# PIC32CZ1038CA70144 register map
Vendor: Microchip Technology; Series: PIC32CZCA70; File version: 0
CPU: CM7 r1p1, little endian, MPU, FPU, double-precision FPU, I-cache, D-cache, ITCM, DTCM, 3 interrupt priority bits, 74 interrupts
Registers are 32-bit, read-write, reset 0x0 unless marked. A register's access mark holds for its fields unless they carry their own. Offsets are from the block's base; [hi:lo] are bit positions; lines under a group give offsets from that group; {n}, {i} and the like mark numbered series; 'fields as' and 'values as' point back to an identical list.

## GMAC — Gigabit Ethernet MAC
Base 0x40050000
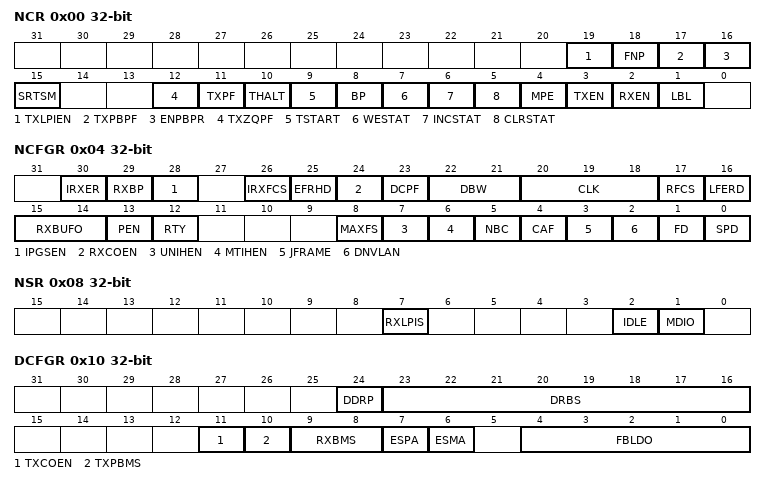
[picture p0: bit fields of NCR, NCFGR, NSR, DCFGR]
0x00 NCR — Network Control Register
  [19] TXLPIEN — Enable LPI Transmission
  [18] FNP — Flush Next Packet
  [17] TXPBPF — Transmit PFC Priority-based Pause Frame
  [16] ENPBPR — Enable PFC Priority-based Pause Reception
  [15] SRTSM — Store Receive Time Stamp to Memory
  [12] TXZQPF — Transmit Zero Quantum Pause Frame
  [11] TXPF — Transmit Pause Frame
  [10] THALT — Transmit Halt
  [9] TSTART — Start Transmission
  [8] BP — Back pressure
  [7] WESTAT — Write Enable for Statistics Registers
  [6] INCSTAT — Increment Statistics Registers
  [5] CLRSTAT — Clear Statistics Registers
  [4] MPE — Management Port Enable
  [3] TXEN — Transmit Enable
  [2] RXEN — Receive Enable
  [1] LBL — Loop Back Local
0x04 NCFGR — Network Configuration Register
  [30] IRXER — Ignore IPG GRXER
  [29] RXBP — Receive Bad Preamble
  [28] IPGSEN — IP Stretch Enable
  [26] IRXFCS — Ignore RX FCS
  [25] EFRHD — Enable Frames Received in Half Duplex
  [24] RXCOEN — Receive Checksum Offload Enable
  [23] DCPF — Disable Copy of Pause Frames
  [22:21] DBW — Data Bus Width
  [20:18] CLK — MDC CLock Division
    0=MCK_8 (MCK divided by 8 (MCK up to 20 MHz)); 1=MCK_16 (MCK divided by 16 (MCK up to 40 MHz)); 2=MCK_32 (MCK divided by 32 (MCK up to 80 MHz)); 3=MCK_48 (MCK divided by 48 (MCK up to 120 MHz)); 4=MCK_64 (MCK divided by 64 (MCK up to 160 MHz)); 5=MCK_96 (MCK divided by 96 (MCK up to 240 MHz))
  [17] RFCS — Remove FCS
  [16] LFERD — Length Field Error Frame Discard
  [15:14] RXBUFO — Receive Buffer Offset
  [13] PEN — Pause Enable
  [12] RTY — Retry Test
  [8] MAXFS — 1536 Maximum Frame Size
  [7] UNIHEN — Unicast Hash Enable
  [6] MTIHEN — Multicast Hash Enable
  [5] NBC — No Broadcast
  [4] CAF — Copy All Frames
  [3] JFRAME — Jumbo Frame Size
  [2] DNVLAN — Discard Non-VLAN FRAMES
  [1] FD — Full Duplex
  [0] SPD — Speed
0x08 NSR ro — Network Status Register
  [7] RXLPIS — LPI Indication
  [2] IDLE — PHY Management Logic Idle
  [1] MDIO — MDIO Input Status
0x0C UR — User Register
  [0] RMII — Reduced MII Mode
0x10 DCFGR — DMA Configuration Register
  [24] DDRP — DMA Discard Receive Packets
  [23:16] DRBS — DMA Receive Buffer Size
  [11] TXCOEN — Transmitter Checksum Generation Offload Enable
  [10] TXPBMS — Transmitter Packet Buffer Memory Size Select
  [9:8] RXBMS — Receiver Packet Buffer Memory Size Select
    0=EIGHTH (4/8 Kbyte Memory Size); 1=QUARTER (4/4 Kbytes Memory Size); 2=HALF (4/2 Kbytes Memory Size); 3=FULL (4 Kbytes Memory Size)
  [7] ESPA — Endian Swap Mode Enable for Packet Data Accesses
  [6] ESMA — Endian Swap Mode Enable for Management Descriptor Accesses
  [4:0] FBLDO — Fixed Burst Length for DMA Data Operations:
    1=SINGLE (00001: Always use SINGLE AHB bursts); 4=INCR4 (001xx: Attempt to use INCR4 AHB bursts (Default)); 8=INCR8 (01xxx: Attempt to use INCR8 AHB bursts); 16=INCR16 (1xxxx: Attempt to use INCR16 AHB bursts)
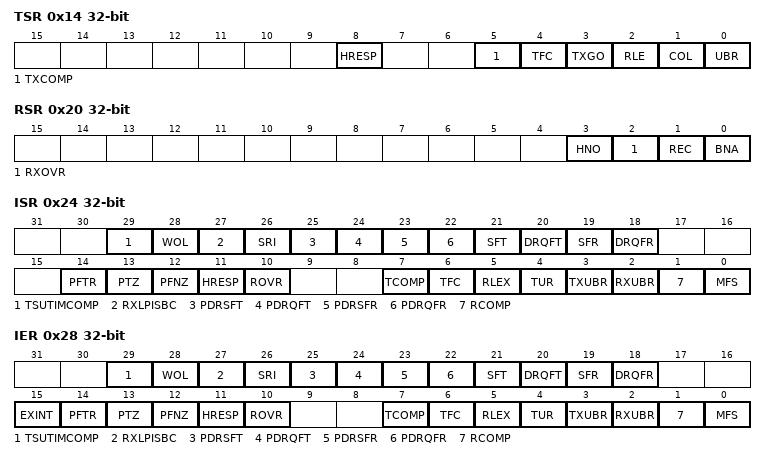
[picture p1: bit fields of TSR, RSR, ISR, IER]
0x14 TSR — Transmit Status Register
  [8] HRESP — HRESP Not OK
  [5] TXCOMP — Transmit Complete
  [4] TFC — Transmit Frame Corruption Due to AHB Error
  [3] TXGO — Transmit Go
  [2] RLE — Retry Limit Exceeded
  [1] COL — Collision Occurred
  [0] UBR — Used Bit Read
0x18 RBQB — Receive Buffer Queue Base Address Register
  [31:2] ADDR — Receive Buffer Queue Base Address
0x1C TBQB — Transmit Buffer Queue Base Address Register
  [31:2] ADDR — Transmit Buffer Queue Base Address
0x20 RSR — Receive Status Register
  [3] HNO — HRESP Not OK
  [2] RXOVR — Receive Overrun
  [1] REC — Frame Received
  [0] BNA — Buffer Not Available
0x24 ISR ro — Interrupt Status Register
  [29] TSUTIMCOMP — TSU Timer Comparison
  [28] WOL — Wake On LAN
  [27] RXLPISBC — Receive LPI indication Status Bit Change
  [26] SRI — TSU Seconds Register Increment
  [25] PDRSFT — PDelay Response Frame Transmitted
  [24] PDRQFT — PDelay Request Frame Transmitted
  [23] PDRSFR — PDelay Response Frame Received
  [22] PDRQFR — PDelay Request Frame Received
  [21] SFT — PTP Sync Frame Transmitted
  [20] DRQFT — PTP Delay Request Frame Transmitted
  [19] SFR — PTP Sync Frame Received
  [18] DRQFR — PTP Delay Request Frame Received
  [14] PFTR — Pause Frame Transmitted
  [13] PTZ — Pause Time Zero
  [12] PFNZ — Pause Frame with Non-zero Pause Quantum Received
  [11] HRESP — HRESP Not OK
  [10] ROVR — Receive Overrun
  [7] TCOMP — Transmit Complete
  [6] TFC — Transmit Frame Corruption Due to AHB Error
  [5] RLEX — Retry Limit Exceeded
  [4] TUR — Transmit Underrun
  [3] TXUBR — TX Used Bit Read
  [2] RXUBR — RX Used Bit Read
  [1] RCOMP — Receive Complete
  [0] MFS — Management Frame Sent
0x28 IER wo — Interrupt Enable Register
  [29] TSUTIMCOMP — TSU Timer Comparison
  [28] WOL — Wake On LAN
  [27] RXLPISBC — Enable RX LPI Indication
  [26] SRI — TSU Seconds Register Increment
  [25] PDRSFT — PDelay Response Frame Transmitted
  [24] PDRQFT — PDelay Request Frame Transmitted
  [23] PDRSFR — PDelay Response Frame Received
  [22] PDRQFR — PDelay Request Frame Received
  [21] SFT — PTP Sync Frame Transmitted
  [20] DRQFT — PTP Delay Request Frame Transmitted
  [19] SFR — PTP Sync Frame Received
  [18] DRQFR — PTP Delay Request Frame Received
  [15] EXINT — External Interrupt
  [14] PFTR — Pause Frame Transmitted
  [13] PTZ — Pause Time Zero
  [12] PFNZ — Pause Frame with Non-zero Pause Quantum Received
  [11] HRESP — HRESP Not OK
  [10] ROVR — Receive Overrun
  [7] TCOMP — Transmit Complete
  [6] TFC — Transmit Frame Corruption Due to AHB Error
  [5] RLEX — Retry Limit Exceeded or Late Collision
  [4] TUR — Transmit Underrun
  [3] TXUBR — TX Used Bit Read
  [2] RXUBR — RX Used Bit Read
  [1] RCOMP — Receive Complete
  [0] MFS — Management Frame Sent
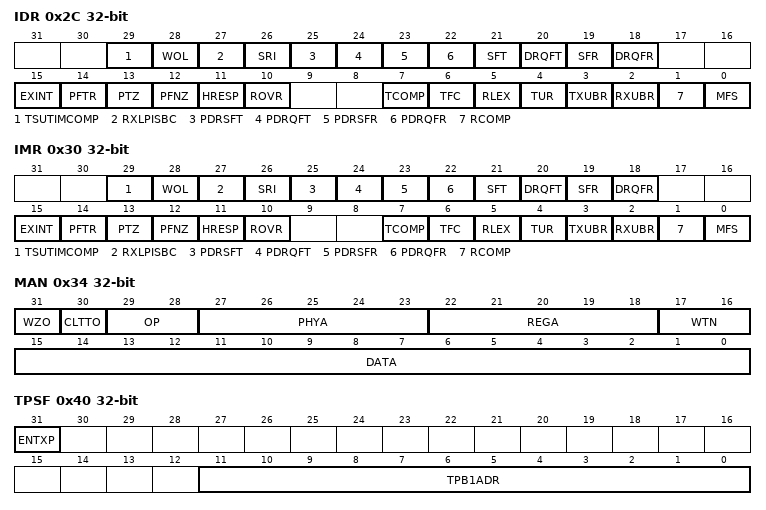
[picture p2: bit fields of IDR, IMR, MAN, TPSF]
0x2C IDR wo — Interrupt Disable Register
  fields as IER
0x30 IMR — Interrupt Mask Register
  [29] TSUTIMCOMP — TSU Timer Comparison
  [28] WOL — Wake On LAN
  [27] RXLPISBC — Enable RX LPI Indication
  [26] SRI — TSU Seconds Register Increment
  [25] PDRSFT — PDelay Response Frame Transmitted
  [24] PDRQFT — PDelay Request Frame Transmitted
  [23] PDRSFR — PDelay Response Frame Received
  [22] PDRQFR — PDelay Request Frame Received
  [21] SFT — PTP Sync Frame Transmitted
  [20] DRQFT — PTP Delay Request Frame Transmitted
  [19] SFR — PTP Sync Frame Received
  [18] DRQFR — PTP Delay Request Frame Received
  [15] EXINT — External Interrupt
  [14] PFTR — Pause Frame Transmitted
  [13] PTZ — Pause Time Zero
  [12] PFNZ — Pause Frame with Non-zero Pause Quantum Received
  [11] HRESP — HRESP Not OK
  [10] ROVR — Receive Overrun
  [7] TCOMP — Transmit Complete
  [6] TFC — Transmit Frame Corruption Due to AHB Error
  [5] RLEX — Retry Limit Exceeded
  [4] TUR — Transmit Underrun
  [3] TXUBR — TX Used Bit Read
  [2] RXUBR — RX Used Bit Read
  [1] RCOMP — Receive Complete
  [0] MFS — Management Frame Sent
0x34 MAN — PHY Maintenance Register
  [31] WZO — Write ZERO
  [30] CLTTO — Clause 22 Operation
  [29:28] OP — Operation
  [27:23] PHYA — PHY Address
  [22:18] REGA — Register Address
  [17:16] WTN — Write Ten
  [15:0] DATA — PHY Data
0x38 RPQ ro — Received Pause Quantum Register
  [15:0] RPQ — Received Pause Quantum
0x3C TPQ — Transmit Pause Quantum Register
  [15:0] TPQ — Transmit Pause Quantum
0x40 TPSF — TX Partial Store and Forward Register
  [31] ENTXP — Enable TX Partial Store and Forward Operation
  [11:0] TPB1ADR — Transmit Partial Store and Forward Address
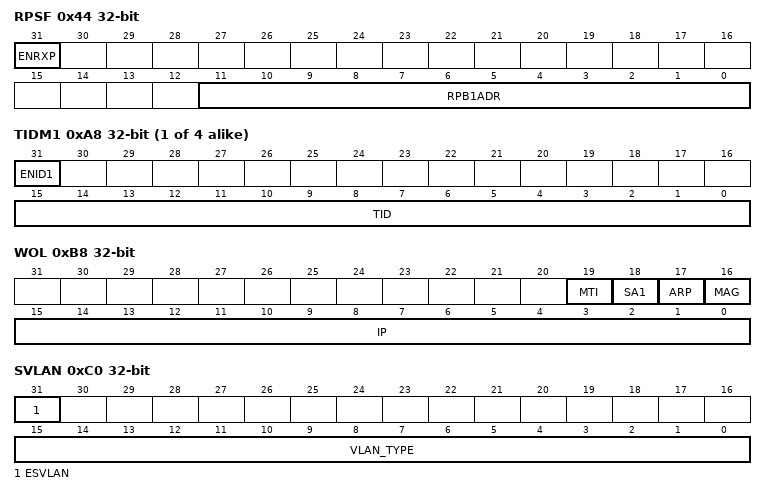
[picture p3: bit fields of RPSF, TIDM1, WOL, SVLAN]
0x44 RPSF — RX Partial Store and Forward Register
  [31] ENRXP — Enable RX Partial Store and Forward Operation
  [11:0] RPB1ADR — Receive Partial Store and Forward Address
0x48 RJFML — RX Jumbo Frame Max Length Register
  [13:0] FML — Frame Max Length
0x80 HRB — Hash Register Bottom
  [31:0] ADDR — Hash Address
0x84 HRT — Hash Register Top
  [31:0] ADDR — Hash Address
{0x80+8i} GMAC_SA{i} (i=1..4) group — Specific Address 1 Bottom Register
  0x00 SAB — Specific Address 1 Bottom Register
    [31:0] ADDR — Specific Address 1
  0x04 SAT — Specific Address 1 Top Register
    [15:0] ADDR — Specific Address 1
{0xA4+4i} TIDM{i} (i=1..4) — Type ID Match {i} Register
  [31] ENID{i} — Enable Copying of TID Matched Frames
  [15:0] TID — Type ID Match {i}
0xB8 WOL — Wake on LAN Register
  [19] MTI — Multicast Hash Event Enable
  [18] SA1 — Specific Address Register 1 Event Enable
  [17] ARP — ARP Request IP Address
  [16] MAG — Magic Packet Event Enable
  [15:0] IP — ARP Request IP Address
0xBC IPGS — IPG Stretch Register
  [15:0] FL — Frame Length
0xC0 SVLAN — Stacked VLAN Register
  [31] ESVLAN — Enable Stacked VLAN Processing Mode
  [15:0] VLAN_TYPE — User Defined VLAN_TYPE Field
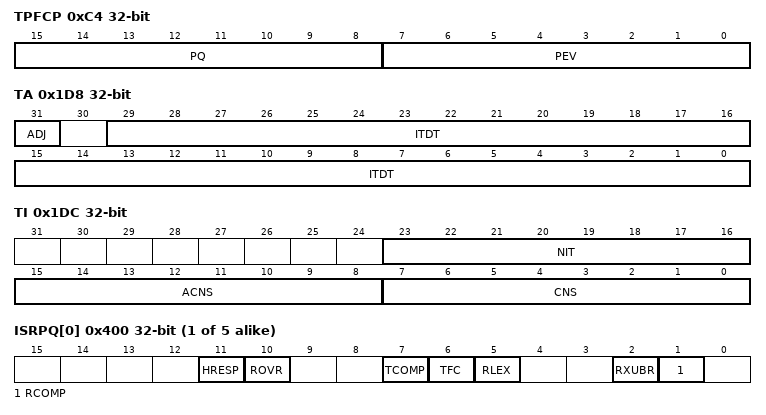
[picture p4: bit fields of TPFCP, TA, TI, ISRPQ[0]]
0xC4 TPFCP — Transmit PFC Pause Register
  [15:8] PQ — Pause Quantum
  [7:0] PEV — Priority Enable Vector
0xC8 SAMB1 — Specific Address 1 Mask Bottom Register
  [31:0] ADDR — Specific Address 1 Mask
0xCC SAMT1 — Specific Address 1 Mask Top Register
  [15:0] ADDR — Specific Address 1 Mask
0xDC NSC — 1588 Timer Nanosecond Comparison Register
  [21:0] NANOSEC — 1588 Timer Nanosecond Comparison Value
0xE0 SCL — 1588 Timer Second Comparison Low Register
  [31:0] SEC — 1588 Timer Second Comparison Value
0xE4 SCH — 1588 Timer Second Comparison High Register
  [15:0] SEC — 1588 Timer Second Comparison Value
0xE8 EFTSH ro — PTP Event Frame Transmitted Seconds High Register
  [15:0] RUD — Register Update
0xEC EFRSH ro — PTP Event Frame Received Seconds High Register
  [15:0] RUD — Register Update
0xF0 PEFTSH ro — PTP Peer Event Frame Transmitted Seconds High Register
  [15:0] RUD — Register Update
0xF4 PEFRSH ro — PTP Peer Event Frame Received Seconds High Register
  [15:0] RUD — Register Update
0x100 OTLO ro — Octets Transmitted Low Register
  [31:0] TXO — Transmitted Octets
0x104 OTHI ro — Octets Transmitted High Register
  [15:0] TXO — Transmitted Octets
0x108 FT ro — Frames Transmitted Register
  [31:0] FTX — Frames Transmitted without Error
0x10C BCFT ro — Broadcast Frames Transmitted Register
  [31:0] BFTX — Broadcast Frames Transmitted without Error
0x110 MFT ro — Multicast Frames Transmitted Register
  [31:0] MFTX — Multicast Frames Transmitted without Error
0x114 PFT ro — Pause Frames Transmitted Register
  [15:0] PFTX
0x118 BFT64 ro — 64 Byte Frames Transmitted Register
  [31:0] NFTX — 64 Byte Frames Transmitted without Error
0x11C TBFT127 ro — 65 to 127 Byte Frames Transmitted Register
  [31:0] NFTX — 65 to 127 Byte Frames Transmitted without Error
0x120 TBFT255 ro — 128 to 255 Byte Frames Transmitted Register
  [31:0] NFTX — 128 to 255 Byte Frames Transmitted without Error
0x124 TBFT511 ro — 256 to 511 Byte Frames Transmitted Register
  [31:0] NFTX — 256 to 511 Byte Frames Transmitted without Error
0x128 TBFT1023 ro — 512 to 1023 Byte Frames Transmitted Register
  [31:0] NFTX — 512 to 1023 Byte Frames Transmitted without Error
0x12C TBFT1518 ro — 1024 to 1518 Byte Frames Transmitted Register
  [31:0] NFTX — 1024 to 1518 Byte Frames Transmitted without Error
0x130 GTBFT1518 ro — Greater Than 1518 Byte Frames Transmitted Register
  [31:0] NFTX — Greater than 1518 Byte Frames Transmitted without Error
0x134 TUR ro — Transmit Underruns Register
  [9:0] TXUNR — Transmit Underruns
0x138 SCF ro — Single Collision Frames Register
  [17:0] SCOL — Single Collision
0x13C MCF ro — Multiple Collision Frames Register
  [17:0] MCOL — Multiple Collision
0x140 EC ro — Excessive Collisions Register
  [9:0] XCOL — Excessive Collisions
0x144 LC ro — Late Collisions Register
  [9:0] LCOL — Late Collisions
0x148 DTF ro — Deferred Transmission Frames Register
  [17:0] DEFT — Deferred Transmission
0x14C CSE ro — Carrier Sense Errors Register
  [9:0] CSR — Carrier Sense Error
0x150 ORLO ro — Octets Received Low Received Register
  [31:0] RXO — Received Octets
0x154 ORHI ro — Octets Received High Received Register
  [15:0] RXO — Received Octets
0x158 FR ro — Frames Received Register
  [31:0] FRX — Frames Received without Error
0x15C BCFR ro — Broadcast Frames Received Register
  [31:0] BFRX — Broadcast Frames Received without Error
0x160 MFR ro — Multicast Frames Received Register
  [31:0] MFRX — Multicast Frames Received without Error
0x164 PFR ro — Pause Frames Received Register
  [15:0] PFRX
0x168 BFR64 ro — 64 Byte Frames Received Register
  [31:0] NFRX — 64 Byte Frames Received without Error
0x16C TBFR127 ro — 65 to 127 Byte Frames Received Register
  [31:0] NFRX — 65 to 127 Byte Frames Received without Error
0x170 TBFR255 ro — 128 to 255 Byte Frames Received Register
  [31:0] NFRX — 128 to 255 Byte Frames Received without Error
0x174 TBFR511 ro — 256 to 511 Byte Frames Received Register
  [31:0] NFRX — 256 to 511 Byte Frames Received without Error
0x178 TBFR1023 ro — 512 to 1023 Byte Frames Received Register
  [31:0] NFRX — 512 to 1023 Byte Frames Received without Error
0x17C TBFR1518 ro — 1024 to 1518 Byte Frames Received Register
  [31:0] NFRX — 1024 to 1518 Byte Frames Received without Error
0x180 TMXBFR ro — 1519 to Maximum Byte Frames Received Register
  [31:0] NFRX — 1519 to Maximum Byte Frames Received without Error
0x184 UFR ro — Undersize Frames Received Register
  [9:0] UFRX — Undersize Frames Received
0x188 OFR ro — Oversize Frames Received Register
  [9:0] OFRX — Oversized Frames Received
0x18C JR ro — Jabbers Received Register
  [9:0] JRX — Jabbers Received
0x190 FCSE ro — Frame Check Sequence Errors Register
  [9:0] FCKR — Frame Check Sequence Errors
0x194 LFFE ro — Length Field Frame Errors Register
  [9:0] LFER — Length Field Frame Errors
0x198 RSE ro — Receive Symbol Errors Register
  [9:0] RXSE — Receive Symbol Errors
0x19C AE ro — Alignment Errors Register
  [9:0] AER — Alignment Errors
0x1A0 RRE ro — Receive Resource Errors Register
  [17:0] RXRER — Receive Resource Errors
0x1A4 ROE ro — Receive Overrun Register
  [9:0] RXOVR — Receive Overruns
0x1A8 IHCE ro — IP Header Checksum Errors Register
  [7:0] HCKER — IP Header Checksum Errors
0x1AC TCE ro — TCP Checksum Errors Register
  [7:0] TCKER — TCP Checksum Errors
0x1B0 UCE ro — UDP Checksum Errors Register
  [7:0] UCKER — UDP Checksum Errors
0x1BC TISUBN — 1588 Timer Increment Sub-nanoseconds Register
  [15:0] LSBTIR — Lower Significant Bits of Timer Increment Register
0x1C0 TSH — 1588 Timer Seconds High Register
  [15:0] TCS — Timer Count in Seconds
0x1D0 TSL — 1588 Timer Seconds Low Register
  [31:0] TCS — Timer Count in Seconds
0x1D4 TN — 1588 Timer Nanoseconds Register
  [29:0] TNS — Timer Count in Nanoseconds
0x1D8 TA wo — 1588 Timer Adjust Register
  [31] ADJ — Adjust 1588 Timer
  [29:0] ITDT — Increment/Decrement
0x1DC TI — 1588 Timer Increment Register
  [23:16] NIT — Number of Increments
  [15:8] ACNS — Alternative Count Nanoseconds
  [7:0] CNS — Count Nanoseconds
0x1E0 EFTSL ro — PTP Event Frame Transmitted Seconds Low Register
  [31:0] RUD — Register Update
0x1E4 EFTN ro — PTP Event Frame Transmitted Nanoseconds Register
  [29:0] RUD — Register Update
0x1E8 EFRSL ro — PTP Event Frame Received Seconds Low Register
  [31:0] RUD — Register Update
0x1EC EFRN ro — PTP Event Frame Received Nanoseconds Register
  [29:0] RUD — Register Update
0x1F0 PEFTSL ro — PTP Peer Event Frame Transmitted Seconds Low Register
  [31:0] RUD — Register Update
0x1F4 PEFTN ro — PTP Peer Event Frame Transmitted Nanoseconds Register
  [29:0] RUD — Register Update
0x1F8 PEFRSL ro — PTP Peer Event Frame Received Seconds Low Register
  [31:0] RUD — Register Update
0x1FC PEFRN ro — PTP Peer Event Frame Received Nanoseconds Register
  [29:0] RUD — Register Update
0x270 RXLPI ro — Received LPI Transitions
  [15:0] COUNT — Count of RX LPI transitions (cleared on read)
0x274 RXLPITIME ro — Received LPI Time
  [23:0] LPITIME — Time in LPI (cleared on read)
0x278 TXLPI ro — Transmit LPI Transitions
  [15:0] COUNT — Count of LPI transitions (cleared on read)
0x27C TXLPITIME ro — Transmit LPI Time
  [23:0] LPITIME — Time in LPI (cleared on read)
{0x400+4i} ISRPQ[{i}] (i=0..4) ro — Interrupt Status Register Priority Queue (1..5)
  [11] HRESP — HRESP Not OK
  [10] ROVR — Receive Overrun
  [7] TCOMP — Transmit Complete
  [6] TFC — Transmit Frame Corruption Due to AHB Error
  [5] RLEX — Retry Limit Exceeded or Late Collision
  [2] RXUBR — RX Used Bit Read
  [1] RCOMP — Receive Complete
{0x440+4i} TBQBAPQ[{i}] (i=0..4) — Transmit Buffer Queue Base Address Register Priority Queue (1..5)
  [31:2] TXBQBA — Transmit Buffer Queue Base Address
{0x480+4i} RBQBAPQ[{i}] (i=0..4) — Receive Buffer Queue Base Address Register Priority Queue (1..5)
  [31:2] RXBQBA — Receive Buffer Queue Base Address
{0x4A0+4i} RBSRPQ[{i}] (i=0..4) — Receive Buffer Size Register Priority Queue (1..5)
  [15:0] RBS — Receive Buffer Size
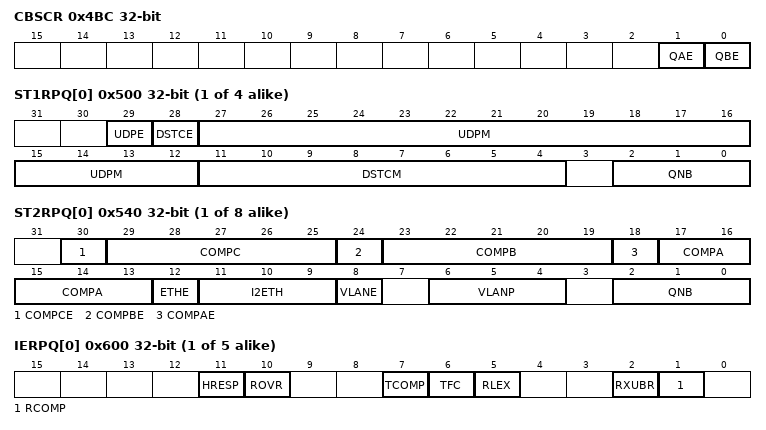
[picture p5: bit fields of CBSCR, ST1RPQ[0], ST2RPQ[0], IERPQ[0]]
0x4BC CBSCR — Credit-Based Shaping Control Register
  [1] QAE — Queue A CBS Enable
  [0] QBE — Queue B CBS Enable
0x4C0 CBSISQA — Credit-Based Shaping IdleSlope Register for Queue A
  [31:0] IS — IdleSlope
0x4C4 CBSISQB — Credit-Based Shaping IdleSlope Register for Queue B
  [31:0] IS — IdleSlope
{0x500+4i} ST1RPQ[{i}] (i=0..3) — Screening Type 1 Register Priority Queue
  [29] UDPE — UDP Port Match Enable
  [28] DSTCE — Differentiated Services or Traffic Class Match Enable
  [27:12] UDPM — UDP Port Match
  [11:4] DSTCM — Differentiated Services or Traffic Class Match
  [2:0] QNB — Queue Number (0-5)
{0x540+4i} ST2RPQ[{i}] (i=0..7) — Screening Type 2 Register Priority Queue
  [30] COMPCE — Compare C Enable
  [29:25] COMPC — Index of Screening Type 2 Compare Word 0/Word 1 register x
  [24] COMPBE — Compare B Enable
  [23:19] COMPB — Index of Screening Type 2 Compare Word 0/Word 1 register x
  [18] COMPAE — Compare A Enable
  [17:13] COMPA — Index of Screening Type 2 Compare Word 0/Word 1 register x
  [12] ETHE — EtherType Enable
  [11:9] I2ETH — Index of Screening Type 2 EtherType register x
  [8] VLANE — VLAN Enable
  [6:4] VLANP — VLAN Priority
  [2:0] QNB — Queue Number (0-5)
{0x600+4i} IERPQ[{i}] (i=0..4) wo — Interrupt Enable Register Priority Queue (1..5)
  fields as ISRPQ[0]
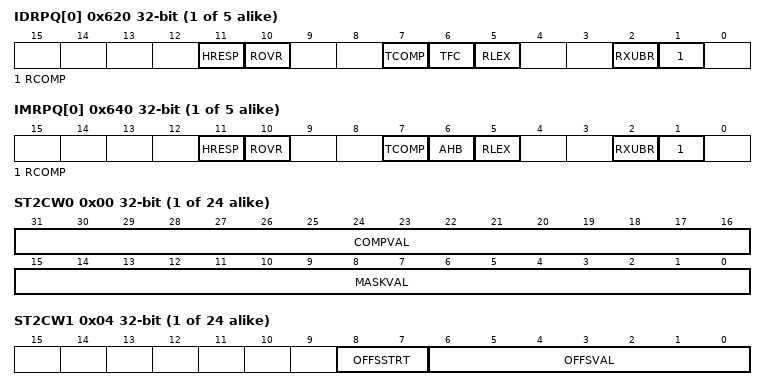
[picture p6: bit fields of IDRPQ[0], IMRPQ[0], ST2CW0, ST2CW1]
{0x620+4i} IDRPQ[{i}] (i=0..4) wo — Interrupt Disable Register Priority Queue (1..5)
  fields as ISRPQ[0]
{0x640+4i} IMRPQ[{i}] (i=0..4) — Interrupt Mask Register Priority Queue (1..5)
  [11] HRESP — HRESP Not OK
  [10] ROVR — Receive Overrun
  [7] TCOMP — Transmit Complete
  [6] AHB — AHB Error
  [5] RLEX — Retry Limit Exceeded or Late Collision
  [2] RXUBR — RX Used Bit Read
  [1] RCOMP — Receive Complete
{0x6E0+4i} ST2ER[{i}] (i=0..3) — Screening Type 2 Ethertype Register
  [15:0] COMPVAL — Ethertype Compare Value
{0x700+8i} GMAC_ST2CW[{i}] (i=0..23) group — Screening Type 2 Compare Word 0 Register
  0x00 ST2CW0 — Screening Type 2 Compare Word 0 Register
    [31:16] COMPVAL — Compare Value
    [15:0] MASKVAL — Mask Value
  0x04 ST2CW1 — Screening Type 2 Compare Word 1 Register
    [8:7] OFFSSTRT — Ethernet Frame Offset Start
      0=FRAMESTART (Offset from the start of the frame); 1=ETHERTYPE (Offset from the byte after the EtherType field); 2=IP (Offset from the byte after the IP header field); 3=TCP_UDP (Offset from the byte after the TCP/UDP header field)
    [6:0] OFFSVAL — Offset Value in Bytes

## Notices in the file
Copyright (c) 2026 Microchip Technology Inc.
SPDX-License-Identifier: Apache-2.0
Licensed under the Apache License, Version 2.0 (the "License");
you may not use this file except in compliance with the License.
You may obtain a copy of the License at
http://www.apache.org/licenses/LICENSE-2.0
Unless required by applicable law or agreed to in writing, software
distributed under the License is distributed on an "AS IS" BASIS,
WITHOUT WARRANTIES OR CONDITIONS OF ANY KIND, either express or implied.
See the License for the specific language governing permissions and
limitations under the License.
